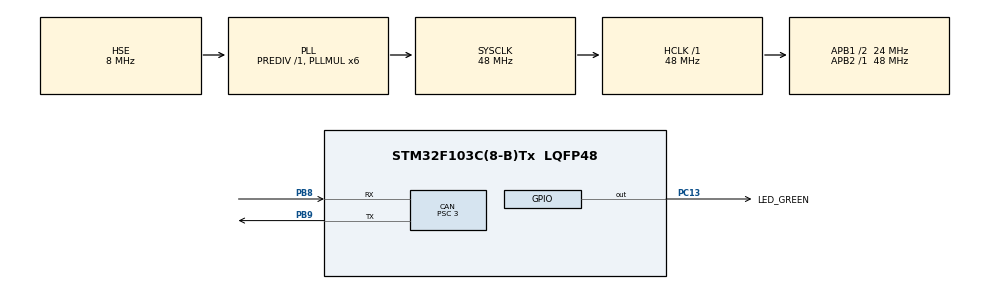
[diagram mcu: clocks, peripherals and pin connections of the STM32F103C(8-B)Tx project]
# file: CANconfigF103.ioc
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CAN.BS1=CAN_BS1_13TQ
CAN.BS2=CAN_BS2_2TQ
CAN.CalculateTimeBit=2000
CAN.CalculateTimeQuantum=125.0
CAN.Prescaler=3
Mcu.Family=STM32F1
Mcu.Name=STM32F103C(8-B)Tx
Mcu.Package=LQFP48
NVIC.PriorityGroup=NVIC_PRIORITYGROUP_4
NVIC.USB_HP_CAN1_TX_IRQn=true\:0\:0\:false\:false\:true\:true\:true
NVIC.USB_LP_CAN1_RX0_IRQn=true\:0\:0\:false\:false\:true\:true\:true
PB8.GPIO_PuPd=GPIO_NOPULL
PB8.Mode=Master
PB8.Signal=CAN_RX
PB9.Mode=Master
PB9.Signal=CAN_TX
PC13-TAMPER-RTC.GPIO_Label=LED_GREEN
PC13-TAMPER-RTC.Signal=GPIO_Output
PD0-OSC_IN.Mode=HSE-External-Oscillator
PD0-OSC_IN.Signal=RCC_OSC_IN
PD1-OSC_OUT.Mode=HSE-External-Oscillator
PD1-OSC_OUT.Signal=RCC_OSC_OUT
ProjectManager.HeapSize=0x200
ProjectManager.StackSize=0x400
ProjectManager.TargetToolchain=SW4STM32
RCC.AHBFreq_Value=48000000
RCC.APB1CLKDivider=RCC_HCLK_DIV2
RCC.APB1Freq_Value=24000000
RCC.APB1TimFreq_Value=48000000
RCC.APB2Freq_Value=48000000
RCC.APB2TimFreq_Value=48000000
RCC.EnbaleCSS=true
RCC.HCLKFreq_Value=48000000
RCC.PLLMUL=RCC_PLL_MUL6
RCC.PLLSourceVirtual=RCC_PLLSOURCE_HSE
RCC.SYSCLKFreq_VALUE=48000000
RCC.SYSCLKSource=RCC_SYSCLKSOURCE_PLLCLK
RCC.USBFreq_Value=48000000
VP_SYS_VS_ND.Mode=No_Debug
board=custom

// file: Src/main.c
/* USER CODE BEGIN Header */
/**
  ******************************************************************************
  * @file           : main.c
  * @brief          : Main program body
  ******************************************************************************
  ** This notice applies to any and all portions of this file
  * that are not between comment pairs USER CODE BEGIN and
  * USER CODE END. Other portions of this file, whether
  * inserted by the user or by software development tools
  * are owned by their respective copyright owners.
  *
  * COPYRIGHT(c) 2019 STMicroelectronics
  *
  * Redistribution and use in source and binary forms, with or without modification,
  * are permitted provided that the following conditions are met:
  *   1. Redistributions of source code must retain the above copyright notice,
  *      this list of conditions and the following disclaimer.
  *   2. Redistributions in binary form must reproduce the above copyright notice,
  *      this list of conditions and the following disclaimer in the documentation
  *      and/or other materials provided with the distribution.
  *   3. Neither the name of STMicroelectronics nor the names of its contributors
  *      may be used to endorse or promote products derived from this software
  *      without specific prior written permission.
  *
  * THIS SOFTWARE IS PROVIDED BY THE COPYRIGHT HOLDERS AND CONTRIBUTORS "AS IS"
  * AND ANY EXPRESS OR IMPLIED WARRANTIES, INCLUDING, BUT NOT LIMITED TO, THE
  * IMPLIED WARRANTIES OF MERCHANTABILITY AND FITNESS FOR A PARTICULAR PURPOSE ARE
  * DISCLAIMED. IN NO EVENT SHALL THE COPYRIGHT HOLDER OR CONTRIBUTORS BE LIABLE
  * FOR ANY DIRECT, INDIRECT, INCIDENTAL, SPECIAL, EXEMPLARY, OR CONSEQUENTIAL
  * DAMAGES (INCLUDING, BUT NOT LIMITED TO, PROCUREMENT OF SUBSTITUTE GOODS OR
  * SERVICES; LOSS OF USE, DATA, OR PROFITS; OR BUSINESS INTERRUPTION) HOWEVER
  * CAUSED AND ON ANY THEORY OF LIABILITY, WHETHER IN CONTRACT, STRICT LIABILITY,
  * OR TORT (INCLUDING NEGLIGENCE OR OTHERWISE) ARISING IN ANY WAY OUT OF THE USE
  * OF THIS SOFTWARE, EVEN IF ADVISED OF THE POSSIBILITY OF SUCH DAMAGE.
  *
  ******************************************************************************
  */
/* USER CODE END Header */

#include "main.h"

CAN_HandleTypeDef hcan;

/* USER CODE BEGIN PV */
CAN_FilterTypeDef sFilterConfig;
CAN_TxHeaderTypeDef TxHeader;
CAN_RxHeaderTypeDef RxHeader;
uint8_t TxData[8];
uint8_t RxData[8];
uint32_t TxMailbox;

/* USER CODE END PV */

void SystemClock_Config(void);
static void MX_GPIO_Init(void);
static void MX_CAN_Init(void);

int main(void)
{

  /* MCU Configuration--------------------------------------------------------*/

  /* Reset of all peripherals, Initializes the Flash interface and the Systick. */
  HAL_Init();

  /* Configure the system clock */
  SystemClock_Config();

  /* Initialize all configured peripherals */
  MX_GPIO_Init();
  MX_CAN_Init();
  /* USER CODE BEGIN 2 */
  sFilterConfig.FilterBank = 0;
  sFilterConfig.FilterMode = CAN_FILTERMODE_IDMASK;
  sFilterConfig.FilterScale = CAN_FILTERSCALE_32BIT;
  sFilterConfig.FilterIdHigh = 0x321 << 5;
  sFilterConfig.FilterIdLow = 0x0000;
  sFilterConfig.FilterMaskIdHigh = 0x0000;
  sFilterConfig.FilterMaskIdLow = 0x0000;
  sFilterConfig.FilterFIFOAssignment = CAN_RX_FIFO0;
  sFilterConfig.FilterActivation = ENABLE;
  sFilterConfig.SlaveStartFilterBank = 14;
  if (HAL_CAN_ConfigFilter(&hcan, &sFilterConfig) != HAL_OK)
  {
	  /* Filter configuration Error */
	  Error_Handler();
  }
  if (HAL_CAN_Start(&hcan) != HAL_OK)
  {
	  /* Start Error */
	  Error_Handler();
  }
  if (HAL_CAN_ActivateNotification(&hcan, CAN_IT_RX_FIFO0_MSG_PENDING | CAN_IT_TX_MAILBOX_EMPTY) != HAL_OK)
  {
	  /* Notification Error */
	  Error_Handler();
  }
  TxHeader.StdId = 0x321;
  TxHeader.ExtId = 0x01;
  TxHeader.RTR = CAN_RTR_DATA;
  TxHeader.IDE = CAN_ID_STD;
  TxHeader.DLC = 8;
  TxHeader.TransmitGlobalTime = DISABLE;
  TxData[0] = 1;
  TxData[1] = 2;
  TxData[2] = 3;
  TxData[3] = 4;
  TxData[4] = 5;
  TxData[5] = 6;
  TxData[6] = 7;
  TxData[7] = 8;

  /* USER CODE END 2 */

  /* Infinite loop */
  while (1)
  {

    /* USER CODE BEGIN 3 */
	  continue;
	if (HAL_CAN_AddTxMessage(&hcan, &TxHeader, TxData, &TxMailbox) != HAL_OK)
	{
		/* Transmission request Error */
		Error_Handler();
	}
	/* Wait transmission complete */
	while(HAL_CAN_GetTxMailboxesFreeLevel(&hcan) != 3) {}
	HAL_Delay(1000);
//	TxData[7] = TxData[7] + 1;
//	  HAL_GPIO_TogglePin(LED_GREEN_GPIO_Port, LED_GREEN_Pin);
  }
  /* USER CODE END 3 */
}

void SystemClock_Config(void)
{
  RCC_OscInitTypeDef RCC_OscInitStruct = {0};
  RCC_ClkInitTypeDef RCC_ClkInitStruct = {0};

  /** Initializes the CPU, AHB and APB busses clocks
  */
  RCC_OscInitStruct.OscillatorType = RCC_OSCILLATORTYPE_HSE;
  RCC_OscInitStruct.HSEState = RCC_HSE_ON;
  RCC_OscInitStruct.HSEPredivValue = RCC_HSE_PREDIV_DIV1;
  RCC_OscInitStruct.HSIState = RCC_HSI_ON;
  RCC_OscInitStruct.PLL.PLLState = RCC_PLL_ON;
  RCC_OscInitStruct.PLL.PLLSource = RCC_PLLSOURCE_HSE;
  RCC_OscInitStruct.PLL.PLLMUL = RCC_PLL_MUL6;
  if (HAL_RCC_OscConfig(&RCC_OscInitStruct) != HAL_OK)
  {
    Error_Handler();
  }
  /** Initializes the CPU, AHB and APB busses clocks
  */
  RCC_ClkInitStruct.ClockType = RCC_CLOCKTYPE_HCLK|RCC_CLOCKTYPE_SYSCLK
                              |RCC_CLOCKTYPE_PCLK1|RCC_CLOCKTYPE_PCLK2;
  RCC_ClkInitStruct.SYSCLKSource = RCC_SYSCLKSOURCE_PLLCLK;
  RCC_ClkInitStruct.AHBCLKDivider = RCC_SYSCLK_DIV1;
  RCC_ClkInitStruct.APB1CLKDivider = RCC_HCLK_DIV2;
  RCC_ClkInitStruct.APB2CLKDivider = RCC_HCLK_DIV1;

  if (HAL_RCC_ClockConfig(&RCC_ClkInitStruct, FLASH_LATENCY_1) != HAL_OK)
  {
    Error_Handler();
  }
  /** Enables the Clock Security System
  */
  HAL_RCC_EnableCSS();
}

static void MX_CAN_Init(void)
{

  hcan.Instance = CAN1;
  hcan.Init.Prescaler = 3;
  hcan.Init.Mode = CAN_MODE_NORMAL;
  hcan.Init.SyncJumpWidth = CAN_SJW_1TQ;
  hcan.Init.TimeSeg1 = CAN_BS1_13TQ;
  hcan.Init.TimeSeg2 = CAN_BS2_2TQ;
  hcan.Init.TimeTriggeredMode = DISABLE;
  hcan.Init.AutoBusOff = DISABLE;
  hcan.Init.AutoWakeUp = DISABLE;
  hcan.Init.AutoRetransmission = DISABLE;
  hcan.Init.ReceiveFifoLocked = DISABLE;
  hcan.Init.TransmitFifoPriority = DISABLE;
  if (HAL_CAN_Init(&hcan) != HAL_OK)
  {
    Error_Handler();
  }

}

static void MX_GPIO_Init(void)
{
  GPIO_InitTypeDef GPIO_InitStruct = {0};

  /* GPIO Ports Clock Enable */
  __HAL_RCC_GPIOC_CLK_ENABLE();
  __HAL_RCC_GPIOD_CLK_ENABLE();
  __HAL_RCC_GPIOB_CLK_ENABLE();

  /*Configure GPIO pin Output Level */
  HAL_GPIO_WritePin(LED_GREEN_GPIO_Port, LED_GREEN_Pin, GPIO_PIN_SET);

  /*Configure GPIO pin : LED_GREEN_Pin */
  GPIO_InitStruct.Pin = LED_GREEN_Pin;
  GPIO_InitStruct.Mode = GPIO_MODE_OUTPUT_PP;
  GPIO_InitStruct.Pull = GPIO_NOPULL;
  GPIO_InitStruct.Speed = GPIO_SPEED_FREQ_LOW;
  HAL_GPIO_Init(LED_GREEN_GPIO_Port, &GPIO_InitStruct);

}

/* USER CODE BEGIN 4 */
void HAL_CAN_TxMailbox0CompleteCallback(CAN_HandleTypeDef *hcan)
{
//	HAL_GPIO_TogglePin(LED_GREEN_GPIO_Port, LED_GREEN_Pin);
}

void HAL_CAN_RxFifo0MsgPendingCallback(CAN_HandleTypeDef *hcan)
{
	if(HAL_CAN_GetRxMessage(hcan, CAN_RX_FIFO0, &RxHeader, RxData) != HAL_OK)
	{
		/* Reception Error */
		Error_Handler();
	}
	HAL_GPIO_TogglePin(LED_GREEN_GPIO_Port, LED_GREEN_Pin);
}

/* USER CODE END 4 */

void Error_Handler(void)
{
  /* USER CODE BEGIN Error_Handler_Debug */
  /* User can add his own implementation to report the HAL error return state */
	while(1)
	{
		HAL_GPIO_TogglePin(LED_GREEN_GPIO_Port, LED_GREEN_Pin);
		HAL_Delay(150);
	}
  /* USER CODE END Error_Handler_Debug */
}

/************************ (C) COPYRIGHT STMicroelectronics *****END OF FILE****/
